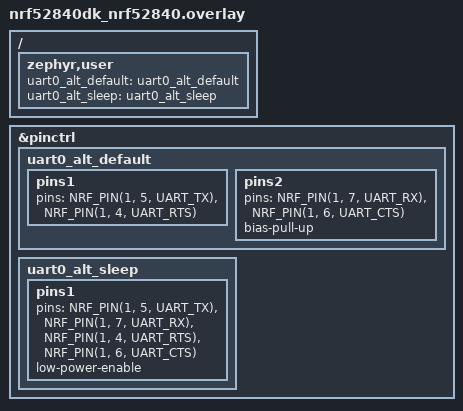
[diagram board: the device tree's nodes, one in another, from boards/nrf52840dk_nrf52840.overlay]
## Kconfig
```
# Copyright (c) 2021 Nordic Semiconductor ASA
# SPDX-License-Identifier: Apache-2.0

mainmenu "Dynamic pin control sample"

config REMAP_INIT_PRIORITY
	int "Remap routine initialization priority"
	default 60
	help
	  Initialization priority of the remap routine within the PRE_KERNEL1 level.
	  This priority must be greater than GPIO_INIT_PRIORITY and lower than
	  UART_INIT_PRIORITY.

source "Kconfig.zephyr"
```

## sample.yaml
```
sample:
  description: A dynamic pin control sample for nRF board/s.
  name: dynamic_pinctrl
```

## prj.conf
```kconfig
CONFIG_PINCTRL_DYNAMIC=y
# Make sure GPIO is initialized before UART. This is required because we need
# to read a GPIO pin to decide if UART pins have to be remapped or not, an
# operation that needs to happen before UART device is initialized.
CONFIG_GPIO_INIT_PRIORITY=50
CONFIG_SERIAL_INIT_PRIORITY=70
CONFIG_UART_CONSOLE_INIT_PRIORITY=80
```

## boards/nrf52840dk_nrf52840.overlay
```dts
/ {
	zephyr,user {
		uart0_alt_default = <&uart0_alt_default>;
		uart0_alt_sleep = <&uart0_alt_sleep>;
	};
};

&pinctrl {
	/* Alternative pins for UART0 */
	uart0_alt_default: uart0_alt_default {
		pins1 {
			pins = <NRF_PIN(1, 5, UART_TX)>,
			       <NRF_PIN(1, 4, UART_RTS)>;
		};
		pins2 {
			pins = <NRF_PIN(1, 7, UART_RX)>,
			       <NRF_PIN(1, 6, UART_CTS)>;
			bias-pull-up;
		};
	};

	uart0_alt_sleep: uart0_alt_sleep {
		pins1 {
			pins = <NRF_PIN(1, 5, UART_TX)>,
			       <NRF_PIN(1, 7, UART_RX)>,
			       <NRF_PIN(1, 4, UART_RTS)>,
			       <NRF_PIN(1, 6, UART_CTS)>;
			low-power-enable;
		};
	};
};
```

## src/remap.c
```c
/*
 * Copyright (c) 2021 Nordic Semiconductor ASA
 *
 * SPDX-License-Identifier: Apache-2.0
 */

#include <device.h>
#include <drivers/gpio.h>
#include <drivers/pinctrl.h>

PINCTRL_DT_DEV_CONFIG_DECLARE(DT_NODELABEL(uart0));

/* UART0 alternative configurations (default and sleep states) */
PINCTRL_DT_STATE_PINS_DEFINE(DT_PATH(zephyr_user), uart0_alt_default);
#ifdef CONFIG_PM_DEVICE
PINCTRL_DT_STATE_PINS_DEFINE(DT_PATH(zephyr_user), uart0_alt_sleep);
#endif

static const struct pinctrl_state uart0_alt[] = {
	PINCTRL_DT_STATE_INIT(uart0_alt_default, PINCTRL_STATE_DEFAULT),
#ifdef CONFIG_PM_DEVICE
	PINCTRL_DT_STATE_INIT(uart0_alt_sleep, PINCTRL_STATE_SLEEP),
#endif
};

static int remap_pins(const struct device *dev)
{
	int ret;
	const struct gpio_dt_spec button = GPIO_DT_SPEC_GET_OR(DT_ALIAS(sw0),
							       gpios, {0});

	ARG_UNUSED(dev);

	if (!device_is_ready(button.port)) {
		return -ENODEV;
	}

	ret = gpio_pin_configure_dt(&button, GPIO_INPUT);
	if (ret < 0) {
		return ret;
	}

	/* remap UART0 pins if button is pressed */
	if (gpio_pin_get_dt(&button)) {
		struct pinctrl_dev_config *uart0_config =
			PINCTRL_DT_DEV_CONFIG_GET(DT_NODELABEL(uart0));

		return pinctrl_update_states(uart0_config, uart0_alt,
					     ARRAY_SIZE(uart0_alt));

	}

	return 0;
}

SYS_INIT(remap_pins, PRE_KERNEL_1, CONFIG_REMAP_INIT_PRIORITY);
```
